# STM32L151xBA register map
File version: 1.0
Registers are 32-bit, read-write, reset 0x0 unless marked. A register's access mark holds for its fields unless they carry their own. Offsets are from the block's base; [hi:lo] are bit positions; {n}, {i} and the like mark numbered series; 'fields as' and 'values as' point back to an identical list.

## DMA1
Base 0x40026000
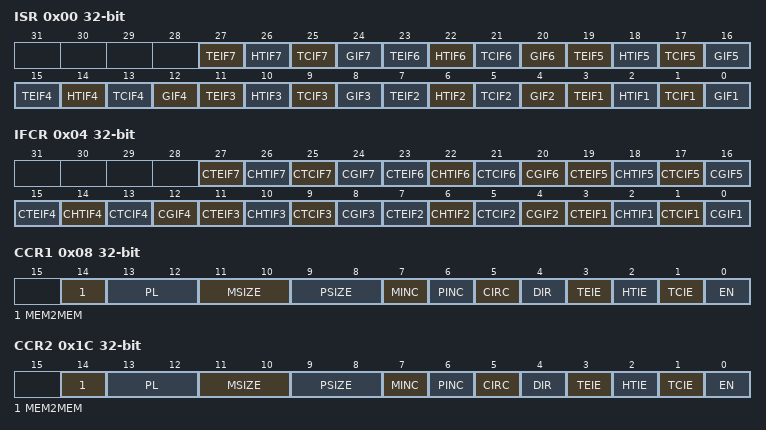
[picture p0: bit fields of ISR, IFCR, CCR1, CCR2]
0x00 ISR — DMA interrupt status register
  [4n-1] TEIF{n} (n=1..7) — Channel {n} Transfer Error flag
  [4n-2] HTIF{n} (n=1..7) — Channel {n} Half Transfer flag
  [4n-3] TCIF{n} (n=1..7) — Channel {n} Transfer Complete flag
  [4n-4] GIF{n} (n=1..7) — Channel {n} Global interrupt flag
0x04 IFCR — DMA interrupt flag clear register
  [4n-1] CTEIF{n} (n=1..7) — Channel {n} Transfer Error clear
  [4n-2] CHTIF{n} (n=1..7) — Channel {n} Half Transfer clear
  [4n-3] CTCIF{n} (n=1..7) — Channel {n} Transfer Complete clear
  [4n-4] CGIF{n} (n=1..7) — Channel {n} Global interrupt clear
0x08 CCR1 — DMA channel x configuration register
  [14] MEM2MEM — Memory to memory mode
  [13:12] PL — PL[1:0] bits(Channel Priority level)
  [11:10] MSIZE — MSIZE[1:0] bits (Memory size)
  [9:8] PSIZE — PSIZE[1:0] bits (Peripheral size)
  [7] MINC — Memory increment mode
  [6] PINC — Peripheral increment mode
  [5] CIRC — Circular mode
  [4] DIR — Data transfer direction
  [3] TEIE — Transfer error interrupt enable
  [2] HTIE — Half Transfer interrupt enable
  [1] TCIE — Transfer complete interrupt enable
  [0] EN — Channel enable
0x0C CNDTR1 — DMA channel x number of data register
  [15:0] NDT — Number of data to Transfer
0x10 CPAR1 — DMA channel x peripheral address register
  [31:0] PA — Peripheral Address
{0x0+0x14*i} CMAR{i} (i=1..7) — DMA channel x memory address register
  [31:0] MA — Memory Address
0x1C CCR2 — DMA channel x configuration register
  fields as CCR1
0x20 CNDTR2 — DMA channel x number of data register
  [15:0] NDT — Number of data to Transfer
0x24 CPAR2 — DMA channel x peripheral address register
  [31:0] PA — Peripheral Address
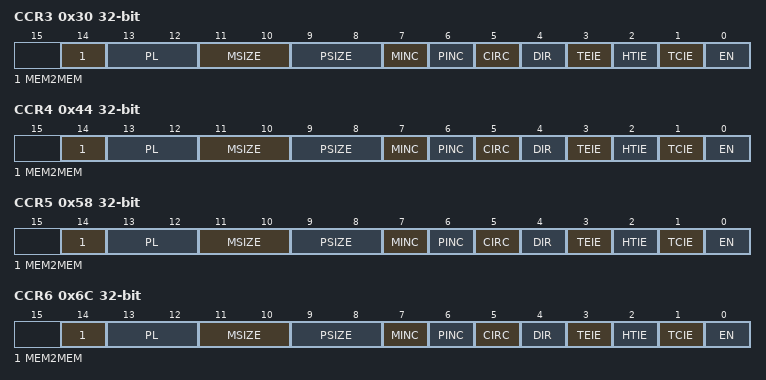
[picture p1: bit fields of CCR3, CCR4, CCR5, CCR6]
0x30 CCR3 — DMA channel x configuration register
  fields as CCR1
0x34 CNDTR3 — DMA channel x number of data register
  [15:0] NDT — Number of data to Transfer
0x38 CPAR3 — DMA channel x peripheral address register
  [31:0] PA — Peripheral Address
0x44 CCR4 — DMA channel x configuration register
  fields as CCR1
0x48 CNDTR4 — DMA channel x number of data register
  [15:0] NDT — Number of data to Transfer
0x4C CPAR4 — DMA channel x peripheral address register
  [31:0] PA — Peripheral Address
0x58 CCR5 — DMA channel x configuration register
  fields as CCR1
0x5C CNDTR5 — DMA channel x number of data register
  [15:0] NDT — Number of data to Transfer
0x60 CPAR5 — DMA channel x peripheral address register
  [31:0] PA — Peripheral Address
0x6C CCR6 — DMA channel x configuration register
  fields as CCR1
0x70 CNDTR6 — DMA channel x number of data register
  [15:0] NDT — Number of data to Transfer
0x74 CPAR6 — DMA channel x peripheral address register
  [31:0] PA — Peripheral Address
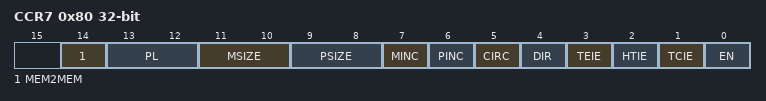
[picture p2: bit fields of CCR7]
0x80 CCR7 — DMA channel x configuration register
  fields as CCR1
0x84 CNDTR7 — DMA channel x number of data register
  [15:0] NDT — Number of data to Transfer
0x88 CPAR7 — DMA channel x peripheral address register
  [31:0] PA — Peripheral Address

## DBGMCU — Debug MCU
Base 0xE0042000
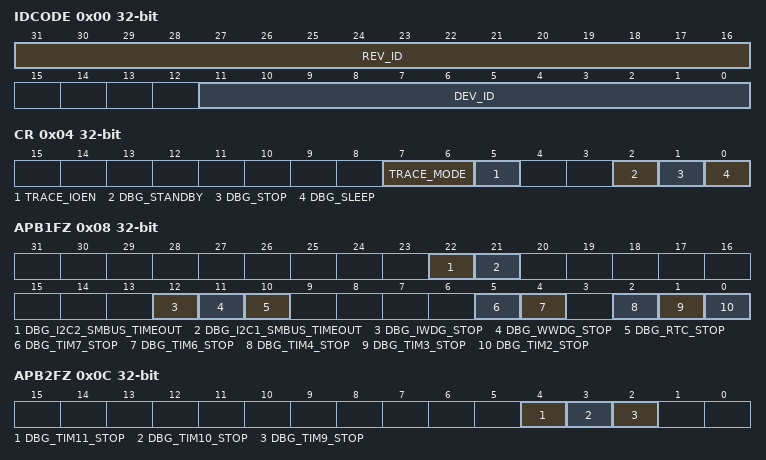
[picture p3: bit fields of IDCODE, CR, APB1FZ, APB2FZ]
0x00 IDCODE — MCU device ID code
  [31:16] REV_ID — REV_ID[15:0] bits (Revision Identifier)
  [11:0] DEV_ID — Device Identifier
0x04 CR — Debug MCU configuration register
  [7:6] TRACE_MODE — TRACE_MODE[1:0] bits (Trace Pin Assignment Control)
  [5] TRACE_IOEN — Trace Pin Assignment Control
  [2] DBG_STANDBY — Debug Standby mode
  [1] DBG_STOP — Debug Stop Mode
  [0] DBG_SLEEP — Debug Sleep Mode
0x08 APB1FZ — Debug MCU APB1 freeze register
  [22] DBG_I2C2_SMBUS_TIMEOUT — SMBUS timeout mode stopped when Core is halted
  [21] DBG_I2C1_SMBUS_TIMEOUT — SMBUS timeout mode stopped when Core is halted
  [12] DBG_IWDG_STOP — Debug Independent Watchdog stopped when Core is halted
  [11] DBG_WWDG_STOP — Debug Window Watchdog stopped when Core is halted
  [10] DBG_RTC_STOP — RTC Counter stopped when Core is halted
  [5] DBG_TIM7_STOP — TIM7 counter stopped when core is halted
  [4] DBG_TIM6_STOP — TIM6 counter stopped when core is halted
  [2] DBG_TIM4_STOP — TIM4 counter stopped when core is halted
  [1] DBG_TIM3_STOP — TIM3 counter stopped when core is halted
  [0] DBG_TIM2_STOP — TIM2 counter stopped when core is halted
0x0C APB2FZ — Debug MCU APB2 freeze register
  [4] DBG_TIM11_STOP — TIM11 counter stopped when core is halted
  [3] DBG_TIM10_STOP — TIM10 counter stopped when core is halted
  [2] DBG_TIM9_STOP — TIM9 counter stopped when core is halted
